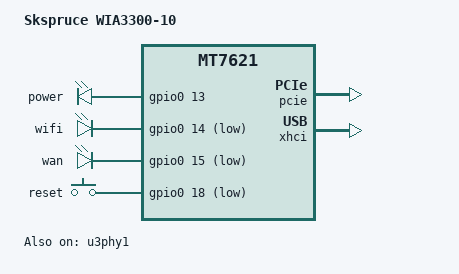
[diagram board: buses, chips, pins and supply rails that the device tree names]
/dts-v1/;

#include "mt7621.dtsi"
#include <dt-bindings/input/input.h>
#include "mt7621-spi-32m-layout.dtsi"
#include "mt7621-raeth-gmac2.dtsi"
#include "mt7621-pinctrl-default-gpio.dtsi"

/ {
	compatible = "mediatek,mt7621-soc";
	model = "Skspruce WIA3300-10";

	chosen {
		bootargs = "console=ttyS0,57600";
	};

	leds {
		compatible = "gpio-leds";

		stat_r {
			label = "power";
			gpios = <&gpio0 13 GPIO_ACTIVE_HIGH>;
		};

		stat_y {
			label = "wifi";
			gpios = <&gpio0 14 GPIO_ACTIVE_LOW>;
		};

		stat_b {
			label = "wan";
			gpios = <&gpio0 15 GPIO_ACTIVE_LOW>;
		};
	};

	gpio-keys-polled {
		compatible = "gpio-keys-polled";
		#address-cells = <1>;
		#size-cells = <0>;
		poll-interval = <20>;

		reset {
			label = "reset";
			gpios = <&gpio0 18 GPIO_ACTIVE_LOW>;
			linux,code = <KEY_RESTART>;
		};
	};
};

&pcie {
	status = "okay";
};

&xhci {
	status = "okay";
};

&u3phy1 {
	status = "okay";
};
